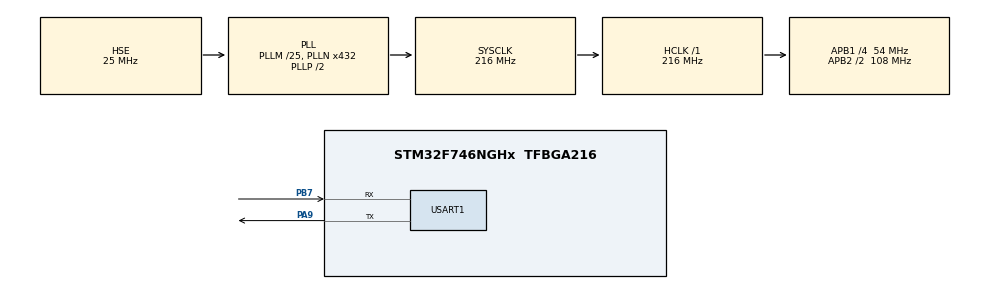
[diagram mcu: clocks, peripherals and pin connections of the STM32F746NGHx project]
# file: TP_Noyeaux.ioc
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FREERTOS.Tasks01=defaultTask,0,128,StartDefaultTask,Default,NULL,Dynamic,NULL,NULL
Mcu.Family=STM32F7
Mcu.Name=STM32F746NGHx
Mcu.Package=TFBGA216
NVIC.PriorityGroup=NVIC_PRIORITYGROUP_4
NVIC.TIM6_DAC_IRQn=true\:15\:0\:false\:false\:true\:false\:false\:true\:true
NVIC.TimeBase=TIM6_DAC_IRQn
NVIC.TimeBaseIP=TIM6
PA13.Mode=Serial_Wire
PA13.Signal=SYS_JTMS-SWDIO
PA14.Mode=Serial_Wire
PA14.Signal=SYS_JTCK-SWCLK
PA9.Mode=Asynchronous
PA9.Signal=USART1_TX
PB7.Mode=Asynchronous
PB7.Signal=USART1_RX
PH0/OSC_IN.Mode=HSE-External-Oscillator
PH0/OSC_IN.Signal=RCC_OSC_IN
PH1/OSC_OUT.Mode=HSE-External-Oscillator
PH1/OSC_OUT.Signal=RCC_OSC_OUT
ProjectManager.HeapSize=0x200
ProjectManager.StackSize=0x400
ProjectManager.TargetToolchain=STM32CubeIDE
RCC.AHBFreq_Value=216000000
RCC.APB1CLKDivider=RCC_HCLK_DIV4
RCC.APB1Freq_Value=54000000
RCC.APB1TimFreq_Value=108000000
RCC.APB2CLKDivider=RCC_HCLK_DIV2
RCC.APB2Freq_Value=108000000
RCC.APB2TimFreq_Value=216000000
RCC.CortexFreq_Value=216000000
RCC.HCLKFreq_Value=216000000
RCC.HSE_VALUE=25000000
RCC.HSI_VALUE=16000000
RCC.LSE_VALUE=32768
RCC.PLLM=25
RCC.PLLN=432
RCC.PLLSourceVirtual=RCC_PLLSOURCE_HSE
RCC.SYSCLKFreq_VALUE=216000000
RCC.SYSCLKSource=RCC_SYSCLKSOURCE_PLLCLK
RCC.USBFreq_Value=216000000
RCC.VCOOutputFreq_Value=432000000
USART1.VirtualMode-Asynchronous=VM_ASYNC
VP_FREERTOS_VS_CMSIS_V1.Mode=CMSIS_V1
VP_SYS_VS_tim6.Mode=TIM6
board=STM32F746G-DISCO

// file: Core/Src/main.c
/* USER CODE BEGIN Header */
/**
 ******************************************************************************
 * @file           : main.c
 * @brief          : Main program body
 ******************************************************************************
 * @attention
 *
 * Copyright (c) 2023 STMicroelectronics.
 * All rights reserved.
 *
 * This software is licensed under terms that can be found in the LICENSE file
 * in the root directory of this software component.
 * If no LICENSE file comes with this software, it is provided AS-IS.
 *
 ******************************************************************************
 */
/* USER CODE END Header */
#include "main.h"
#include "cmsis_os.h"
#include "usart.h"
#include "gpio.h"

/* USER CODE BEGIN PTD */
#define STACK_SIZE 1000
#define Q_UART1_LENGTH 10
#define Q_UART1_SIZE sizeof(int)
/* USER CODE END PTD */

/* USER CODE BEGIN PD */

//SemaphoreHandle_t sem1;

uint8_t input_char;
TaskHandle_t h_task_usart1 = NULL;
TaskHandle_t h_task_tim1 = NULL;
QueueHandle_t q_usart1 = NULL;
/* New character on USART1 */
void USART1_IRQHandler(void){
	BaseType_t higher_priority_task_woken = pdFALSE;
	vTaskNotifyGiveFromISR(h_task_usart1,
			&higher_priority_task_woken);
	HAL_UART_Receive_IT(&huart1, &input_char, 1);
	HAL_UART_IRQHandler(&huart1);
	portYIELD_FROM_ISR(higher_priority_task_woken);
}
/* USER CODE END PD */

void SystemClock_Config(void);
void MX_FREERTOS_Init(void);

/* USER CODE BEGIN 0 */
// TODO écrire le code de la tache
/*    void codeTache (void * pvParameters) {
      int compteur = 0;
      int toto;
      int duree = (int) pvParameters;
      char* s = pcTaskGetName(xTaskGetCurrentTaskHandle());
      while (1) {
      HAL_GPIO_TogglePin(GPIOI, LED_Pin);
      int toto = HAL_GPIO_ReadPin(GPIOI, LED_Pin);
      printf("La Led est a l'etat %d et je m'endors pour %d periodes\n\r", toto, duree);
      vTaskDelay(duree);
      compteur++;
      }
      }
 */

TaskHandle_t xHandleGive = NULL;
TaskHandle_t xHandleTake = NULL;

void taskGive(void *p){
	//	char higher_priority_task_woken = "toto";

	int counter = 0;

	for(;;){
		//		printf("Avant sem Give \r\n");
		//		xTaskNotifyGive(xHandleTake);
		//		printf("Apres sem Give \r\n");
		//		;
		printf("Avant queue send %d\r\n", counter);
		xQueueSend(q_usart1, (void *)&counter, portMAX_DELAY);	// recopie la valeur pointée dans la queue
		printf("Après queue send %d \r\n", counter);

		vTaskDelay(1000);
		counter ++;
	}

}

void taskTake(void *p){
	int counter_received;
	for(;;){
		printf("avant queue receive \r\n");
//
//		ulTaskNotifyTake(pdTRUE, portMAX_DELAY);
		xQueueReceive(q_usart1, (void *)&counter_received, portMAX_DELAY);	// recopie la valeur de la queue vers la variable pointée
		printf("apres queue receive %d \r\n", counter_received);
	}
}

/* USER CODE END 0 */

int __io_putchar(int ch) {
	HAL_UART_Transmit(&huart1, (uint8_t *)&ch, 1, HAL_MAX_DELAY);
	return ch;
}
int main(void)
{
	/* USER CODE BEGIN 1 */
	BaseType_t xReturned;
	TaskHandle_t xHandle1 = NULL;

	/* USER CODE END 1 */

	/* MCU Configuration--------------------------------------------------------*/

	/* Reset of all peripherals, Initializes the Flash interface and the Systick. */
	HAL_Init();

	/* Configure the system clock */
	SystemClock_Config();

	/* Initialize all configured peripherals */
	MX_GPIO_Init();
	MX_USART1_UART_Init();
	/* USER CODE BEGIN 2 */
	// TODO créer la tâche
	//sem1 = xSemaphoreCreateBinary();
	//    xReturned = xTaskCreate(
	//    codeTache, /* Function that implements the task. */
	//    "Task1", /* Text name for the task. */
	//    STACK_SIZE, /* Stack size in words, not bytes. */
	//    (void *) DELAY_1, /* Parameter passed into the task. */
	//    tskIDLE_PRIORITY,/* Priority at which the task is created. */
	//    &xHandle1 ); /* Used to pass out the created task's handle. */
	q_usart1 = xQueueCreate(Q_UART1_LENGTH, Q_UART1_SIZE);

	xReturned = xTaskCreate(
			taskGive, /* Function that implements the task. */
			"Task1", /* Text name for the task. */
			STACK_SIZE, /* Stack size in words, not bytes. */
			NULL, /* Parameter passed into the task. */
			tskIDLE_PRIORITY+1,/* Priority at which the task is created. */
			&xHandleGive ); /* Used to pass out the created task's handle. */

	xReturned = xTaskCreate(
			taskTake, /* Function that implements the task. */
			"Task2", /* Text name for the task. */
			STACK_SIZE, /* Stack size in words, not bytes. */
			NULL, /* Parameter passed into the task. */
			tskIDLE_PRIORITY+2,/* Priority at which the task is created. */
			&xHandleTake ); /* Used to pass out the created task's handle. */

	vTaskStartScheduler();
	/* USER CODE END 2 */

	/* Call init function for freertos objects (in freertos.c) */
	MX_FREERTOS_Init();

	/* Start scheduler */
	osKernelStart();

	/* We should never get here as control is now taken by the scheduler */
	/* Infinite loop */
	while (1)
	{

	}
}

void SystemClock_Config(void)
{
	RCC_OscInitTypeDef RCC_OscInitStruct = {0};
	RCC_ClkInitTypeDef RCC_ClkInitStruct = {0};

	/** Configure the main internal regulator output voltage
	 */
	__HAL_RCC_PWR_CLK_ENABLE();
	__HAL_PWR_VOLTAGESCALING_CONFIG(PWR_REGULATOR_VOLTAGE_SCALE1);

	/** Initializes the RCC Oscillators according to the specified parameters
	 * in the RCC_OscInitTypeDef structure.
	 */
	RCC_OscInitStruct.OscillatorType = RCC_OSCILLATORTYPE_HSE;
	RCC_OscInitStruct.HSEState = RCC_HSE_ON;
	RCC_OscInitStruct.PLL.PLLState = RCC_PLL_ON;
	RCC_OscInitStruct.PLL.PLLSource = RCC_PLLSOURCE_HSE;
	RCC_OscInitStruct.PLL.PLLM = 25;
	RCC_OscInitStruct.PLL.PLLN = 432;
	RCC_OscInitStruct.PLL.PLLP = RCC_PLLP_DIV2;
	RCC_OscInitStruct.PLL.PLLQ = 2;
	if (HAL_RCC_OscConfig(&RCC_OscInitStruct) != HAL_OK)
	{
		Error_Handler();
	}

	/** Activate the Over-Drive mode
	 */
	if (HAL_PWREx_EnableOverDrive() != HAL_OK)
	{
		Error_Handler();
	}

	/** Initializes the CPU, AHB and APB buses clocks
	 */
	RCC_ClkInitStruct.ClockType = RCC_CLOCKTYPE_HCLK|RCC_CLOCKTYPE_SYSCLK
			|RCC_CLOCKTYPE_PCLK1|RCC_CLOCKTYPE_PCLK2;
	RCC_ClkInitStruct.SYSCLKSource = RCC_SYSCLKSOURCE_PLLCLK;
	RCC_ClkInitStruct.AHBCLKDivider = RCC_SYSCLK_DIV1;
	RCC_ClkInitStruct.APB1CLKDivider = RCC_HCLK_DIV4;
	RCC_ClkInitStruct.APB2CLKDivider = RCC_HCLK_DIV2;

	if (HAL_RCC_ClockConfig(&RCC_ClkInitStruct, FLASH_LATENCY_7) != HAL_OK)
	{
		Error_Handler();
	}
}

void HAL_TIM_PeriodElapsedCallback(TIM_HandleTypeDef *htim)
{
	if (htim->Instance == TIM6) {
		HAL_IncTick();
	}
}

void Error_Handler(void)
{
	__disable_irq();
	while (1)
	{
	}
}
